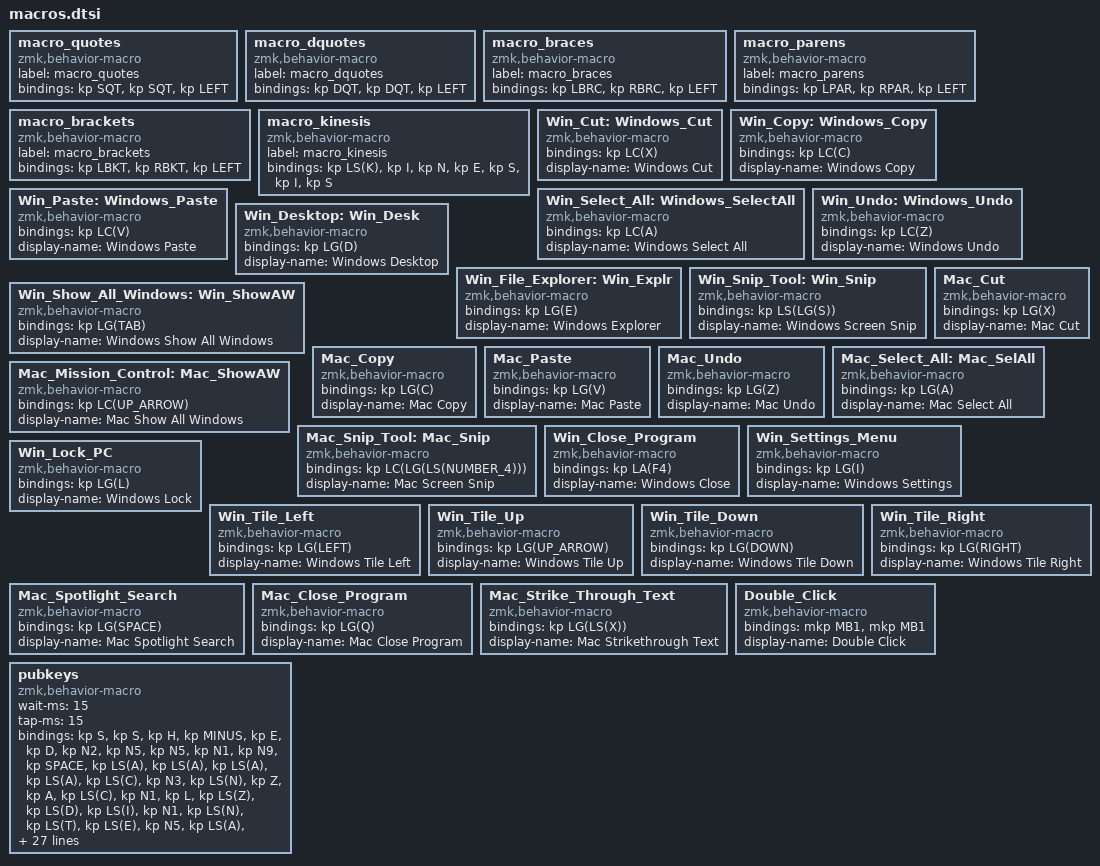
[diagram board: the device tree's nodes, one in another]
  macro_quotes: macro_quotes {
    compatible = "zmk,behavior-macro";
    label = "macro_quotes";
    #binding-cells = <0>;
    bindings = <&kp SQT>, <&kp SQT>, <&kp LEFT>;
  };
  macro_dquotes: macro_dquotes {
    compatible = "zmk,behavior-macro";
    label = "macro_dquotes";
    #binding-cells = <0>;
    bindings = <&kp DQT>, <&kp DQT>, <&kp LEFT>;
  };
  macro_braces: macro_braces {
    compatible = "zmk,behavior-macro";
    label = "macro_braces";
    #binding-cells = <0>;
    bindings = <&kp LBRC>, <&kp RBRC>, <&kp LEFT>;
  };
  macro_parens: macro_parens {
    compatible = "zmk,behavior-macro";
    label = "macro_parens";
    #binding-cells = <0>;
    bindings = <&kp LPAR>, <&kp RPAR>, <&kp LEFT>;
  };
  macro_brackets: macro_brackets {
    compatible = "zmk,behavior-macro";
    label = "macro_brackets";
    #binding-cells = <0>;
    bindings = <&kp LBKT>, <&kp RBKT>, <&kp LEFT>;
  };
  macro_kinesis: macro_kinesis {
    compatible = "zmk,behavior-macro";
    label = "macro_kinesis";
    #binding-cells = <0>;
    bindings = <&kp LS(K)>, <&kp I>, <&kp N>, <&kp E>, <&kp S>, <&kp I>, <&kp S>;
  };
  Win_Cut: Windows_Cut {
    compatible = "zmk,behavior-macro";
    #binding-cells = <0>;
    bindings = <&kp LC(X)>;
    display-name = "Windows Cut";
  };

  Win_Copy: Windows_Copy {
    compatible = "zmk,behavior-macro";
    #binding-cells = <0>;
    bindings = <&kp LC(C)>;
    display-name = "Windows Copy";
  };

  Win_Paste: Windows_Paste {
    compatible = "zmk,behavior-macro";
    #binding-cells = <0>;
    bindings = <&kp LC(V)>;
    display-name = "Windows Paste";
  };

  Win_Select_All: Windows_SelectAll {
      compatible = "zmk,behavior-macro";
      #binding-cells = <0>;
      bindings = <&kp LC(A)>;
      display-name = "Windows Select All";
  };

  Win_Undo: Windows_Undo {
    compatible = "zmk,behavior-macro";
    #binding-cells = <0>;
    bindings = <&kp LC(Z)>;
    display-name = "Windows Undo";
  };

  Win_Desktop: Win_Desk {
    compatible = "zmk,behavior-macro";
    #binding-cells = <0>;
    bindings = <&kp LG(D)>;
    display-name = "Windows Desktop";
  };

  Win_File_Explorer: Win_Explr {
    compatible = "zmk,behavior-macro";
    #binding-cells = <0>;
    bindings = <&kp LG(E)>;
    display-name = "Windows Explorer";
  };

  Win_Snip_Tool: Win_Snip {
    compatible = "zmk,behavior-macro";
    #binding-cells = <0>;
    bindings = <&kp LS(LG(S))>;
    display-name = "Windows Screen Snip";
  };

  Win_Show_All_Windows: Win_ShowAW {
    compatible = "zmk,behavior-macro";
    #binding-cells = <0>;
    bindings = <&kp LG(TAB)>;
    display-name = "Windows Show All Windows";
  };

  Mac_Cut: Mac_Cut {
    compatible = "zmk,behavior-macro";
    #binding-cells = <0>;
    bindings = <&kp LG(X)>;
    display-name = "Mac Cut";
  };

  Mac_Copy: Mac_Copy {
    compatible = "zmk,behavior-macro";
    #binding-cells = <0>;
    bindings = <&kp LG(C)>;
    display-name = "Mac Copy";
  };

  Mac_Paste: Mac_Paste {
    compatible = "zmk,behavior-macro";
    #binding-cells = <0>;
    bindings = <&kp LG(V)>;
    display-name = "Mac Paste";
  };

  Mac_Undo: Mac_Undo {
    compatible = "zmk,behavior-macro";
    #binding-cells = <0>;
    bindings = <&kp LG(Z)>;
    display-name = "Mac Undo";
  };

  Mac_Select_All: Mac_SelAll {
    compatible = "zmk,behavior-macro";
    #binding-cells = <0>;
    bindings = <&kp LG(A)>;
    display-name = "Mac Select All";
  };

  Mac_Mission_Control: Mac_ShowAW {
    compatible = "zmk,behavior-macro";
    #binding-cells = <0>;
    bindings = <&kp LC(UP_ARROW)>;
    display-name = "Mac Show All Windows";
  };

  Mac_Snip_Tool: Mac_Snip {
    compatible = "zmk,behavior-macro";
    #binding-cells = <0>;
    bindings = <&kp LC(LG(LS(NUMBER_4)))>;
    display-name = "Mac Screen Snip";
  };

  Win_Close_Program: Win_Close_Program {
    compatible = "zmk,behavior-macro";
    #binding-cells = <0>;
    bindings = <&kp LA(F4)>;
    display-name = "Windows Close";
  };

  Win_Settings_Menu: Win_Settings_Menu {
    compatible = "zmk,behavior-macro";
    #binding-cells = <0>;
    bindings = <&kp LG(I)>;
    display-name = "Windows Settings";
  };

  Win_Lock_PC: Win_Lock_PC {
    compatible = "zmk,behavior-macro";
    #binding-cells = <0>;
    bindings = <&kp LG(L)>;
    display-name = "Windows Lock";
  };

  Win_Tile_Left: Win_Tile_Left {
    compatible = "zmk,behavior-macro";
    #binding-cells = <0>;
    bindings = <&kp LG(LEFT)>;
    display-name = "Windows Tile Left";
  };

  Win_Tile_Up: Win_Tile_Up {
    compatible = "zmk,behavior-macro";
    #binding-cells = <0>;
    bindings = <&kp LG(UP_ARROW)>;
    display-name = "Windows Tile Up";
  };

  Win_Tile_Down: Win_Tile_Down {
    compatible = "zmk,behavior-macro";
    #binding-cells = <0>;
    bindings = <&kp LG(DOWN)>;
    display-name = "Windows Tile Down";
  };

  Win_Tile_Right: Win_Tile_Right {
    compatible = "zmk,behavior-macro";
    #binding-cells = <0>;
    bindings = <&kp LG(RIGHT)>;
    display-name = "Windows Tile Right";
  };

  Mac_Spotlight_Search: Mac_Spotlight_Search {
    compatible = "zmk,behavior-macro";
    #binding-cells = <0>;
    bindings = <&kp LG(SPACE)>;
    display-name = "Mac Spotlight Search";
  };

  Mac_Close_Program: Mac_Close_Program {
    compatible = "zmk,behavior-macro";
    #binding-cells = <0>;
    bindings = <&kp LG(Q)>;
    display-name = "Mac Close Program";
  };

  Mac_Strike_Through_Text: Mac_Strike_Through_Text {
    compatible = "zmk,behavior-macro";
    #binding-cells = <0>;
    bindings = <&kp LG(LS(X))>;
    display-name = "Mac Strikethrough Text";
  };

  Double_Click: Double_Click {
    compatible = "zmk,behavior-macro";
    #binding-cells = <0>;
    bindings = <&mkp MB1 &mkp MB1>;
    display-name = "Double Click";
  };

  // Types both SSH public keys from github.com/skyar-ch.keys.
  // ssh-ed25519 AAAAC3NzaC1lZDI1NTE5AAAAIO68kQDJGryUSfjOzvoQBMnZKkUyseoXUU+MmwEtDxek
  // ssh-ed25519 AAAAC3NzaC1lZDI1NTE5AAAAIFwvfHCaGgWF7dbsAUSmj2VrcMy69Zsw0aYDGN141PJ8
  pubkeys: pubkeys {
    compatible = "zmk,behavior-macro";
    #binding-cells = <0>;
    wait-ms = <15>;
    tap-ms = <15>;
    bindings
      = <&kp S &kp S &kp H &kp MINUS &kp E &kp D &kp N2 &kp N5 &kp N5 &kp N1 &kp N9 &kp SPACE &kp LS(A) &kp LS(A) &kp LS(A) &kp LS(A) &kp LS(C) &kp N3 &kp LS(N) &kp Z &kp A &kp LS(C) &kp N1 &kp L &kp LS(Z) &kp LS(D) &kp LS(I) &kp N1 &kp LS(N) &kp LS(T) &kp LS(E) &kp N5 &kp LS(A) &kp LS(A) &kp LS(A) &kp LS(A) &kp LS(I) &kp LS(O) &kp N6 &kp N8 &kp K &kp LS(Q) &kp LS(D) &kp LS(J) &kp LS(G) &kp R &kp Y &kp LS(U) &kp LS(S) &kp F &kp J &kp LS(O) &kp Z &kp V &kp O &kp LS(Q) &kp LS(B) &kp LS(M) &kp N &kp LS(Z) &kp LS(K) &kp K &kp LS(U) &kp Y &kp S &kp E &kp O &kp LS(X) &kp LS(U) &kp LS(U) &kp PLUS &kp LS(M) &kp M &kp W &kp LS(E) &kp T &kp LS(D) &kp X &kp E &kp K>
      , <&kp LS(RET)>
      , <&kp S &kp S &kp H &kp MINUS &kp E &kp D &kp N2 &kp N5 &kp N5 &kp N1 &kp N9 &kp SPACE &kp LS(A) &kp LS(A) &kp LS(A) &kp LS(A) &kp LS(C) &kp N3 &kp LS(N) &kp Z &kp A &kp LS(C) &kp N1 &kp L &kp LS(Z) &kp LS(D) &kp LS(I) &kp N1 &kp LS(N) &kp LS(T) &kp LS(E) &kp N5 &kp LS(A) &kp LS(A) &kp LS(A) &kp LS(A) &kp LS(I) &kp LS(F) &kp W &kp V &kp F &kp LS(H) &kp LS(C) &kp A &kp LS(G) &kp G &kp LS(W) &kp LS(F) &kp N7 &kp D &kp B &kp S &kp LS(A) &kp LS(U) &kp LS(S) &kp M &kp J &kp N2 &kp LS(V) &kp R &kp C &kp LS(M) &kp Y &kp N6 &kp N9 &kp LS(Z) &kp S &kp W &kp N0 &kp A &kp LS(Y) &kp LS(D) &kp LS(G) &kp LS(N) &kp N1 &kp N4 &kp N1 &kp LS(P) &kp LS(J) &kp N8>
      ;
    display-name = "Public Keys";
  };
